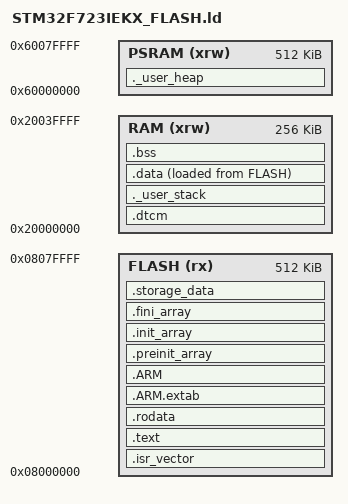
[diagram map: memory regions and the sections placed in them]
/*
******************************************************************************
**
** @file        : LinkerScript.ld
**
** @author      : Auto-generated by STM32CubeIDE
**
**  Abstract    : Linker script for STM32F723E-DISCO Board embedding STM32F723IEKx Device from stm32f7 series
**                      512Kbytes FLASH
**                      256Kbytes RAM
**
**                Set heap size, stack size and stack location according
**                to application requirements.
**
**                Set memory bank area and size if external memory is used
**
**  Target      : STMicroelectronics STM32
**
**  Distribution: The file is distributed as is, without any warranty
**                of any kind.
**
******************************************************************************
** @attention
**
** Copyright (c) 2023 STMicroelectronics.
** All rights reserved.
**
** This software is licensed under terms that can be found in the LICENSE file
** in the root directory of this software component.
** If no LICENSE file comes with this software, it is provided AS-IS.
**
******************************************************************************
*/

/* Entry Point */
ENTRY(Reset_Handler)

/* Memories definition */
MEMORY
{
  RAM     (xrw)    : ORIGIN = 0x20000000,   LENGTH = 256K
  FLASH    (rx)    : ORIGIN = 0x08000000,   LENGTH = 512K
  PSRAM   (xrw)    : ORIGIN = 0x60000000,   LENGTH = 512K
}

_Min_Heap_Size = 128*1024; /* required amount of heap */
_Min_Stack_Size = 0x1000; /* required amount of stack */

/* Heap start and end addresses in PSRAM */
__heap_end = ORIGIN(PSRAM) + LENGTH(PSRAM); /* end of "PSRAM" Ram type memory */
/* __heap_end = _estack - _Min_Stack_Size; */

__fast_ram_start = ORIGIN(RAM);
__fast_ram_end = ORIGIN(RAM) + LENGTH(RAM) - _Min_Stack_Size;

/* Sections */
SECTIONS
{
  /* The startup code into "FLASH" Rom type memory */
  .isr_vector :
  {
    . = ALIGN(4);
    KEEP(*(.isr_vector)) /* Startup code */
    . = ALIGN(4);
  } >FLASH

  /* The program code and other data into "FLASH" Rom type memory */
  .text :
  {
    . = ALIGN(4);
    *(.text)           /* .text sections (code) */
    *(.text*)          /* .text* sections (code) */
    *(.glue_7)         /* glue arm to thumb code */
    *(.glue_7t)        /* glue thumb to arm code */
    *(.eh_frame)

    KEEP (*(.init))
    KEEP (*(.fini))

    . = ALIGN(4);
    _etext = .;        /* define a global symbols at end of code */
  } >FLASH

  /* Constant data into "FLASH" Rom type memory */
  .rodata :
  {
    . = ALIGN(4);
    *(.rodata)         /* .rodata sections (constants, strings, etc.) */
    *(.rodata*)        /* .rodata* sections (constants, strings, etc.) */
    . = ALIGN(4);
  } >FLASH

  .ARM.extab (READONLY)   : {
    . = ALIGN(4);
    *(.ARM.extab* .gnu.linkonce.armextab.*)
    . = ALIGN(4);
  } >FLASH

  .ARM (READONLY) : {
    . = ALIGN(4);
    __exidx_start = .;
    *(.ARM.exidx*)
    __exidx_end = .;
    . = ALIGN(4);
  } >FLASH

  .preinit_array (READONLY)     :
  {
    . = ALIGN(4);
    PROVIDE_HIDDEN (__preinit_array_start = .);
    KEEP (*(.preinit_array*))
    PROVIDE_HIDDEN (__preinit_array_end = .);
    . = ALIGN(4);
  } >FLASH

  .init_array (READONLY) :
  {
    . = ALIGN(4);
    PROVIDE_HIDDEN (__init_array_start = .);
    KEEP (*(SORT(.init_array.*)))
    KEEP (*(.init_array*))
    PROVIDE_HIDDEN (__init_array_end = .);
    . = ALIGN(4);
  } >FLASH

  .fini_array (READONLY) :
  {
    . = ALIGN(4);
    PROVIDE_HIDDEN (__fini_array_start = .);
    KEEP (*(SORT(.fini_array.*)))
    KEEP (*(.fini_array*))
    PROVIDE_HIDDEN (__fini_array_end = .);
    . = ALIGN(4);
  } >FLASH

  /* Uninitialized data section into "RAM" Ram type memory */
  .dtcm (NOLOAD) :
  {
    . = ALIGN(32);
    _sdtcm = .; /* start of DTCM data */
    *(.dtcm)
    *(.dtcm*)
    *(COMMON)
    . = ALIGN(32);
    _edtcm = .; /* start of DTCM data */
  } >RAM

  /* User_stack section, used to check that there is enough "RAM" Ram  type memory left */
  ._user_stack (NOLOAD) :
  {
    . = ALIGN(32);
    _sstack = .;
    . = . + _Min_Stack_Size;
    . = ALIGN(32);
    _estack = .; /* end of stack Ram type memory */
  } >RAM

  /* Used by the startup to initialize data */
  _sidata = LOADADDR(.data);

  /* Initialized data sections into "RAM" Ram type memory */
  .data :
  {
    . = ALIGN(4);
    _sdata = .;        /* create a global symbol at data start */
    *(.data)           /* .data sections */
    *(.data*)          /* .data* sections */
    *(.RamFunc)        /* .RamFunc sections */
    *(.RamFunc*)       /* .RamFunc* sections */

    . = ALIGN(4);
    _edata = .;        /* define a global symbol at data end */

  } >RAM AT> FLASH

  /* User storage section, used to check that there is enough "FLASH" type memory left */
  .storage_data (NOLOAD) :
  {
    . = ALIGN(4);
    . = . + 32768;
    . = ALIGN(4);
  } >FLASH

  /* Uninitialized data section into "RAM" Ram type memory */
  . = ALIGN(4);
  .bss :
  {
    /* This is used by the startup in order to initialize the .bss section */
    _sbss = .;         /* define a global symbol at bss start */
    __bss_start__ = _sbss;
    *(.bss)
    *(.bss*)
    *(COMMON)

    . = ALIGN(4);
    _ebss = .;         /* define a global symbol at bss end */
    __bss_end__ = _ebss;
  } >RAM

  /* User_heap section, used to check that there is enough "PSRAM" Ram  type memory left */
  ._user_heap :
  {
    . = ALIGN(8);
    PROVIDE ( __heap_start = . );
    . = . + _Min_Heap_Size;
    . = ALIGN(8);
  } >PSRAM

  /* Remove information from the compiler libraries */
  /DISCARD/ :
  {
    libc.a ( * )
    libm.a ( * )
    libgcc.a ( * )
  }

  .ARM.attributes 0 : { *(.ARM.attributes) }
}
